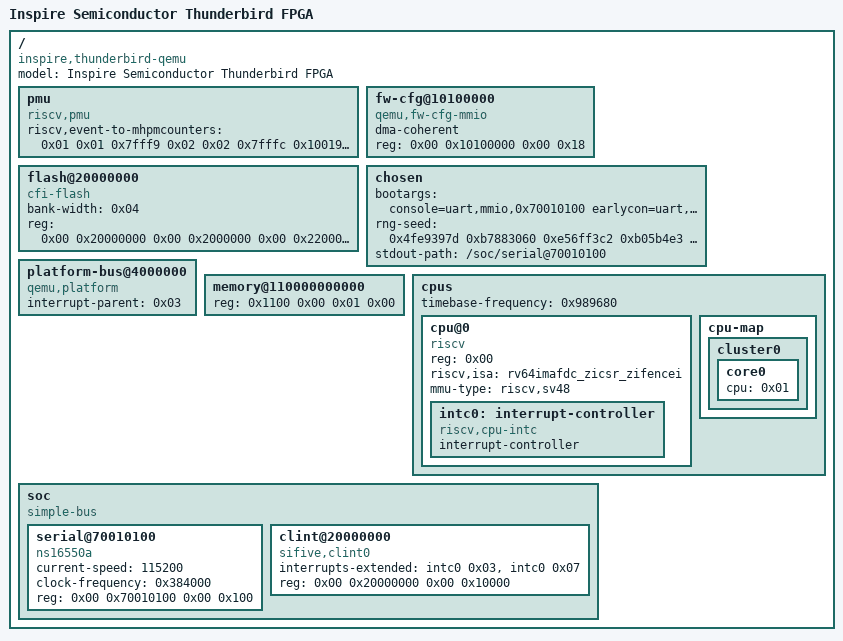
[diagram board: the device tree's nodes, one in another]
/dts-v1/;

/ {
	#address-cells = <0x02>;
	#size-cells = <0x02>;
	compatible = "inspire,thunderbird-qemu", "inspire,thunderbird";
	model = "Inspire Semiconductor Thunderbird FPGA";

	pmu {
		riscv,event-to-mhpmcounters = <0x01 0x01 0x7fff9 0x02 0x02 0x7fffc 0x10019 0x10019 0x7fff8 0x1001b 0x1001b 0x7fff8 0x10021 0x10021 0x7fff8>;
		compatible = "riscv,pmu";
	};

	fw-cfg@10100000 {
		dma-coherent;
		reg = <0x00 0x10100000 0x00 0x18>;
		compatible = "qemu,fw-cfg-mmio";
	};

	flash@20000000 {
		bank-width = <0x04>;
		reg = <0x00 0x20000000 0x00 0x2000000 0x00 0x22000000 0x00 0x2000000>;
		compatible = "cfi-flash";
	};

	chosen {
		bootargs = "console=uart,mmio,0x70010100 earlycon=uart,mmio,0x70010100 debug  rodata=off root=/dev/ram0";
		rng-seed = <0x4fe9397d 0xb7883060 0xe56ff3c2 0xb05b4e3 0x62e5479c 0xd932a9c8 0x95a47b5b 0x192ef245>;
		stdout-path = "/soc/serial@70010100";
	};

		platform-bus@4000000 {
		interrupt-parent = <0x03>;
		ranges = <0x00 0x00 0x4000000 0x2000000>;
		#address-cells = <0x01>;
		#size-cells = <0x01>;
		compatible = "qemu,platform\0simple-bus";
	};

	memory@110000000000 {
		device_type = "memory";
		reg = <0x1100 0x00 0x01 0x00>;
	};

	cpus {
		#address-cells = <0x01>;
		#size-cells = <0x00>;
		timebase-frequency = <0x989680>;

		cpu@0 {
			phandle = <0x01>;
			device_type = "cpu";
			reg = <0x00>;
			status = "okay";
			compatible = "riscv";
			riscv,isa = "rv64imafdc_zicsr_zifencei";
			mmu-type = "riscv,sv48";

			intc0: interrupt-controller {
				#interrupt-cells = <0x01>;
				interrupt-controller;
				compatible = "riscv,cpu-intc";
				phandle = <0x02>;
			};
		};

		cpu-map {

			cluster0 {

				core0 {
					cpu = <0x01>;
				};
			};
		};
	};

	soc {
		#address-cells = <0x02>;
		#size-cells = <0x02>;
		compatible = "simple-bus";
		ranges;

		serial@70010100 {
			current-speed = <115200>;
			clock-frequency = <0x384000>;
			reg = <0x00 0x70010100 0x00 0x100>;
			compatible = "ns16550a";
		};

		clint@20000000 {
			interrupts-extended = <&intc0 0x03 &intc0 0x07>;
			reg = <0x00 0x20000000 0x00 0x10000>;
			compatible = "sifive,clint0", "riscv,clint0";
		};
	};
};
